# NUC505_v1 register map
File version: 1.0
Registers are 32-bit, read-write, reset 0x0 unless marked. A register's access mark holds for its fields unless they carry their own. Offsets are from the block's base; [hi:lo] are bit positions; 'fields as' and 'values as' point back to an identical list.

## SDH — SDH Register Map
Base 0x4000A000
0x00 SDH_FB_N — SDH Receiving/Transmit Flash Buffer
  [31:0] DATA — SDH Receiving/Transmit Flash Buffer. This buffer is used to receive/transmit data. It can be accessed by CPU or DMAC.
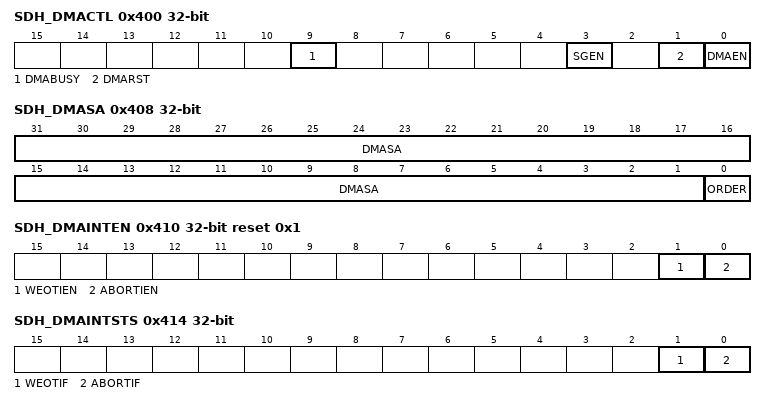
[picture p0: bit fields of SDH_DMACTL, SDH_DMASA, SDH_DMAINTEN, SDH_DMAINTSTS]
0x400 SDH_DMACTL — DMAC Control and Status Register
  [9] DMABUSY — DMA Transfer in Progress. This bit indicates that the DMA is transferred or not.
    0=DMA transfer is not in progress; 1=DMA transfer is in progress
  [3] SGEN — Scatter-gather Function Enable Control
    0=Scatter-gather function Disabled (DMAC will treat the starting address in SDH_DMASA as starting pointer of a single block memory); 1=Scatter-gather function Enabled (DMAC will treat the starting address in SDH_DMASA as a starting address of Physical Address Descriptor (PAD) table. The format of these PADs' will be described later)
  [1] DMARST — Software Engine Reset. Note: Software resets DMA region.
    0=No effect; 1=Reset internal state machine and pointers. The contents of control register will not be cleared. This bit will auto be cleared after few clock cycles
  [0] DMAEN — DMAC Engine Enable Control. Note1: If this bit is cleared, DMAC will ignore all DMA request and force Bus Master into IDLE state. Note2: If a target abort occurs, DMAEN will be cleared.
    0=DMAC Disabled; 1=DMAC Enabled
0x408 SDH_DMASA — DMAC Transfer Starting Address Register
  [31:1] DMASA — DMA Transfer Starting Address. This field pads 0 as least significant bit indicates a 32-bit starting address of system memory (SRAM) for DMAC to retrieve or fill in data. If DMAC is not in Normal mode, this field will be interpreted as a starting address of Physical Address Descriptor (PAD) table. Note: The address can't be set smaller than 0x2000_0000.
  [0] ORDER — Determined to the PAD Table Fetching in Order or Out of Order
    0=PAD table is fetched in order; 1=PAD table is fetched out of order
0x40C SDH_DMABCNT ro — DMAC Transfer Byte Count Register
  [25:0] BCNT — DMA Transfer Byte Count (Read Only). This field indicates the remained byte count of DMAC transfer. The value of this field is valid only when DMAC is busy; otherwise, it is 0.
0x410 SDH_DMAINTEN reset 0x1 — DMAC Interrupt Enable Control Register
  [1] WEOTIEN — Wrong EOT Encountered Interrupt Enable Control
    0=Interrupt generation Disabled when wrong EOT is encountered; 1=Interrupt generation Enabled when wrong EOT is encountered
  [0] ABORTIEN — DMA Read/Write Target Abort Interrupt Enable Control
    0=Target abort interrupt generation Disabled during DMA transfer; 1=Target abort interrupt generation Enabled during DMA transfer
0x414 SDH_DMAINTSTS — DMAC Interrupt Status Register
  [1] WEOTIF — Wrong EOT Encountered Interrupt Flag. When DMA Scatter-Gather function is enabled, and EOT of the descriptor is encountered before DMA transfer finished (that means the total sector count of all PAD is less than the sector count of DMAC), this bit will be set. Note: This bit is read only, but can be cleared by writing '1' to it.
    0=No EOT encountered before DMA transfer finished; 1=EOT encountered before DMA transfer finished
  [0] ABORTIF — DMA Read/Write Target Abort Interrupt Flag. Note: This bit is read only, but can be cleared by writing '1' to it.
    0=No bus ERROR response received; 1=Bus ERROR response received
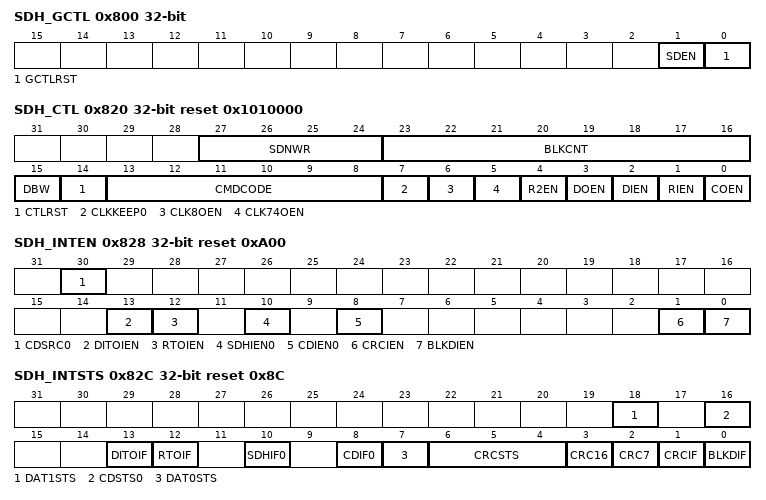
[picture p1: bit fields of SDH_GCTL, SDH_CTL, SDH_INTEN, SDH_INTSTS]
0x800 SDH_GCTL — Global Control and Status Register
  [1] SDEN — Secure-digital Functionality Enable Control
    0=SD functionality Disabled; 1=SD functionality Enabled
  [0] GCTLRST — Software Engine Reset
    0=No effect; 1=Reset all SDH engines. The contents of control registers will not be cleared. This bit will auto cleared after few clock cycles
0x804 SDH_GINTEN reset 0x1 — Global Interrupt Control Register
  [0] DTAIEN — DMAC READ/WRITE Target Abort Interrupt Enable Control
    0=DMAC READ/WRITE target abort interrupt generation Disabled; 1=DMAC READ/WRITE target abort interrupt generation Enabled
0x808 SDH_GINTSTS — Global Interrupt Status Register
  [0] DTAIF ro — DMAC READ/WRITE Target Abort Interrupt Flag (Read Only). This bit indicates DMAC received an ERROR response from internal AHB bus during DMA read/write operation. When Target Abort is occurred, please reset all engines. Note: This bit is read only, but can be cleared by writing '1' to it.
    values as SDH_DMAINTSTS.ABORTIF
0x820 SDH_CTL reset 0x1010000 — SD Control and Status Register
  [27:24] SDNWR — NWR Parameter for Block Write Operation. This value indicates the NWR parameter for data block write operation in SD clock counts. The actual clock cycle will be SDNWR+1.
  [23:16] BLKCNT — Block Counts to Be Transferred or Received. This field contains the block counts for data-in and data-out transfer. For READ_MULTIPLE_BLOCK and WRITE_MULTIPLE_BLOCK command, software can use this function to accelerate data transfer and improve performance. Don't fill 0x0 to this field. For READ_MULTIPLE_BLOCK and WRITE_MULTIPLE_BLOCK command, the actual total length is BLKCNT * (BLKLEN +1).
  [15] DBW — SD Data Bus Width (for 1-bit / 4-bit Selection)
    0=Data bus width is 1-bit; 1=Data bus width is 4-bit
  [14] CTLRST — Software Engine Reset
    0=No effect; 1=Reset the internal state machine and counters. The contents of control register will not be cleared (but RIEN, DIEN, DOEN and R2EN will be cleared). This bit will be auto cleared after few clock cycles
  [13:8] CMDCODE — SD Command Code. This register contains the SD command code (0x00 - 0x3F).
  [7] CLKKEEP0 — SD Clock Enable Control for Port 0
    0=SD host decides when to output clock and when to disable clock output automatically; 1=SD clock always keeps free running
  [6] CLK8OEN — Generating 8 Clock Cycles Output Enable Control. Note: When operation is finished, this bit will be cleared automatically. Thus, don't write 0 to this bit (the controller will be abnormal).
    0=No effect. (Please use SDH_CTL[CTLRST] to clear this bit.); 1=Enabled, and SD host will output 8 clock cycles
  [5] CLK74OEN — Generating 74 Clock Cycles Output Enable Control. Note: When operation is finished, this bit will be cleared automatically. Thus, don't write 0 to this bit (the controller will be abnormal).
    0=No effect. (Please use SDH_CTL[CTLRST] to clear this bit.); 1=Enabled, SD host will output 74 clock cycles to SD card
  [4] R2EN — Response R2 Input Enable Control. Note: When operation is finished, this bit will be cleared automatically. Thus, don't write 0 to this bit (the controller will be abnormal).
    0=No effect. (Please use SDH_CTL[CTLRST] to clear this bit.); 1=Enabled, SD host will wait to receive a response R2 from SD card and store the response data into DMAC's flash buffer (exclude CRC-7)
  [3] DOEN — Data Output Enable Control. Note: When operation is finished, this bit will be cleared automatically. Thus, don't write 0 to this bit (the controller will be abnormal).
    0=No effect. (Please use SDH_CTL[CTLRST] to clear this bit.); 1=Enabled, SD host will transfer block data and the CRC-16 value to SD card
  [2] DIEN — Data Input Enable Control. Note: When operation is finished, this bit will be cleared automatically. Thus, don't write 0 to this bit (the controller will be abnormal).
    0=No effect. (Please use SDH_CTL[CTLRST] to clear this bit.); 1=Enabled, SD host will wait to receive block data and the CRC-16 value from SD card
  [1] RIEN — Response Input Enable Control. Note: When operation is finished, this bit will be cleared automatically. Thus, don't write 0 to this bit (the controller will be abnormal).
    0=No effect. (Please use SDH_CTL[CTLRST] to clear this bit.); 1=Enabled, SD host will wait to receive a response from SD card
  [0] COEN — Command Output Enable Control. Note: When operation is finished, this bit will be cleared automatically. Thus, don't write 0 to this bit (the controller will be abnormal).
    0=No effect. (Please use SDH_CTL[CTLRST] to clear this bit.); 1=Enabled, SD host will output a command to SD card
0x824 SDH_CMDARG — SD Command Argument Register
  [31:0] ARGUMENT — SD Command Argument. This register contains a 32-bit value specifies the argument of SD command from host controller to SD card. Before triggering SDH_CTL [COEN], software should fill argument in this field.
0x828 SDH_INTEN reset 0xA00 — SD Interrupt Control Register
  [30] CDSRC0 — SD0 Card Detect Source Selection
    0=From SD0 card's DAT3 pin; 1=From GPIO pin
  [13] DITOIEN — Data Input Time-out Interrupt Enable Control. Enable/Disable interrupt generation of SD controller when data input time-out. Time-out value is specified at TOUT.
    0=Data Input Time-out Interrupt Disabled; 1=Data Input Time-out Interrupt Enabled
  [12] RTOIEN — Response Time-out Interrupt Enable Control. Enable/Disable interrupt generation of SD controller when receiving response or R2 time-out. Time-out value is specified at TOUT.
    0=Response Time-out Interrupt Disabled; 1=Response Time-out Interrupt Enabled
  [10] SDHIEN0 — SDH Interrupt Enable Control for Port 0. Enable/Disable interrupt generation of SD host when SDH card 0 issues an interrupt via DAT [1] to host.
    0=SDH Port 0 Interrupt Disabled; 1=SDH Port 0 Interrupt Enabled
  [8] CDIEN0 — SD0 Card Detection Interrupt Enable Control. Enable/Disable interrupt generation of SD controller when card 0 is inserted or removed.
    0=SD0 Card Detection Interrupt Disabled; 1=SD0 Card Detection Interrupt Enabled
  [1] CRCIEN — CRC7, CRC16 and CRC Status Error Interrupt Enable Control
    0=SD host will not generate interrupt when CRC7, CRC16 and CRC status is error; 1=SD host will generate interrupt when CRC7, CRC16 and CRC status is error
  [0] BLKDIEN — Block Transfer Done Interrupt Enable Control
    0=SD host will not generate interrupt when data-in (out) transfer done; 1=SD host will generate interrupt when data-in (out) transfer done
0x82C SDH_INTSTS reset 0x8C (reset mask 0xFFF0FFFF) — SD Interrupt Status Register
  [18] DAT1STS ro — DAT1 Pin Status of SD Port (Read Only). This bit indicates the DAT1 pin status of SD port.
  [16] CDSTS0 ro — Card Detect Status of SD0 (Read Only). This bit indicates the card detect pin status of SD0, and is used for card detection. When there is a card inserted in or removed from SD0, software should check this bit to confirm if there is really a card insertion or removal.
    0=Card removed. Card inserted; 1=Card inserted. Card removed
  [13] DITOIF ro — Data Input Time-out Interrupt Flag (Read Only). This bit indicates that SD host counts to time-out value when receiving data (waiting start bit). Note: This bit is read only, but can be cleared by writing '1' to it.
    0=No time-out; 1=Data input time-out
  [12] RTOIF ro — Response Time-out Interrupt Flag (Read Only). This bit indicates that SD host counts to time-out value when receiving response or R2 (waiting start bit). Note: This bit is read only, but can be cleared by writing '1' to it.
    0=No time-out; 1=Response time-out
  [10] SDHIF0 ro — SDH 0 Interrupt Flag (Read Only). This bit indicates that SDH card 0 issues an interrupt to host. This interrupt is designed to level sensitive. Before clearing it, turn off SDHIEN0 (SDH_INTEN[10]) first. Note: This bit is read only, but can be cleared by writing '1' to it.
    0=No interrupt is issued by SDH card 0; 1=an interrupt is issued by SDH card 0
  [8] CDIF0 ro — SD0 Card Detection Interrupt Flag (Read Only). This bit indicates that SD card 0 is inserted or removed. Only when CDIEN0 (SDH_INTEN[8]) is set to 1, this bit is active. Note: This bit is read only, but can be cleared by writing '1' to it.
    0=No card is inserted or removed; 1=There is a card inserted in or removed from SD0
  [7] DAT0STS ro — DAT0 Pin Status of Current Selected SD Port (Read Only). This bit is the DAT0 pin status of current selected SD port.
  [6:4] CRCSTS ro — CRC Status Value of Data-out Transfer (Read Only). SD host will record CRC status of data-out transfer. Software could use this value to identify what type of error is during data-out transfer.
    2=Positive CRC status; 5=Negative CRC status; 7=SD card programming error occurs
  [3] CRC16 ro — CRC-16 Check Status of Data-in Transfer (Read Only). SD host will check CRC-16 correctness after data-in transfer.
    0=CRC-16 Transfer incorrectness; 1=CRC-16 Transfer correctness
  [2] CRC7 ro — CRC-7 Check Status (Read Only). SD host will check CRC-7 correctness during each response in. If that response does not contain CRC-7 information (e.g. R3), then software should turn off CRCIEN (SDH_INTEN[1]) and ignore this bit.
    0=CRC-7 Transfer incorrectness; 1=CRC-7 Transfer correctness
  [1] CRCIF ro — CRC7, CRC16 and CRC Status Error Interrupt Flag (Read Only). This bit indicates that SD host has occurred CRC error during response in, data-in or data-out (CRC status error) transfer. When CRC error occurred, software should reset SD engine. Some responses (e.g. R3) do not have CRC-7 information with it; the SD host will still calculate CRC-7, get CRC error and set this flag. In this condition, software should ignore CRC error and clear this bit manually. Note: This bit is read only, but can be cleared by writing '1' to it.
    0=No CRC error is occurred; 1=CRC error is occurred
  [0] BLKDIF ro — Block Transfer Done Interrupt Flag (Read Only). This bit indicates that SD host has finished all data-in or data-out block transfer. If there is a CRC16 error or incorrect CRC status during multiple block data transfer, the transfer will be broken and this bit will also be set. Note: This bit is read only, but can be cleared by writing '1' to it.
    0=Not finished yet; 1=Done
0x830 SDH_RESP0 ro — SD Receiving Response Token Register 0
  [31:0] RESPTK0 — SD Receiving Response Token 0. SD host controller will receive a response token for getting a reply from SD card when RIEN (SDH_CTL[1]) is set. This field contains response bit 47-16 of the response token.
0x834 SDH_RESP1 ro — SD Receiving Response Token Register 1
  [7:0] RESPTK1 — SD Receiving Response Token 1. SD host controller will receive a response token for getting a reply from SD card when RIEN (SDH_CTL[1]) is set. This register contains the bit 15-8 of the response token.
0x838 SDH_BLEN reset 0x1FF — SD Block Length Register
  [10:0] BLKLEN — SD BLOCK LENGTH in Byte Unit. An 11-bit value specifies the SD transfer byte count of a block. The actual byte count is equal to BLKLEN +1. Note: The default SD block length is 512 bytes.
0x83C SDH_TOUT — SD Response/Data-in Time-out Register
  [23:0] TOUT — SD Response/Data-in Time-out Value. A 24-bit value specifies the time-out count of response and data input. SD host controller will wait the start bit of response or data-in until this value reached. The time period depends on SD engine clock frequency. Do not write a small number into this field, or you may never get response or data due to time-out. Note: Filling 0x0 into this field will disable hardware time-out function.
